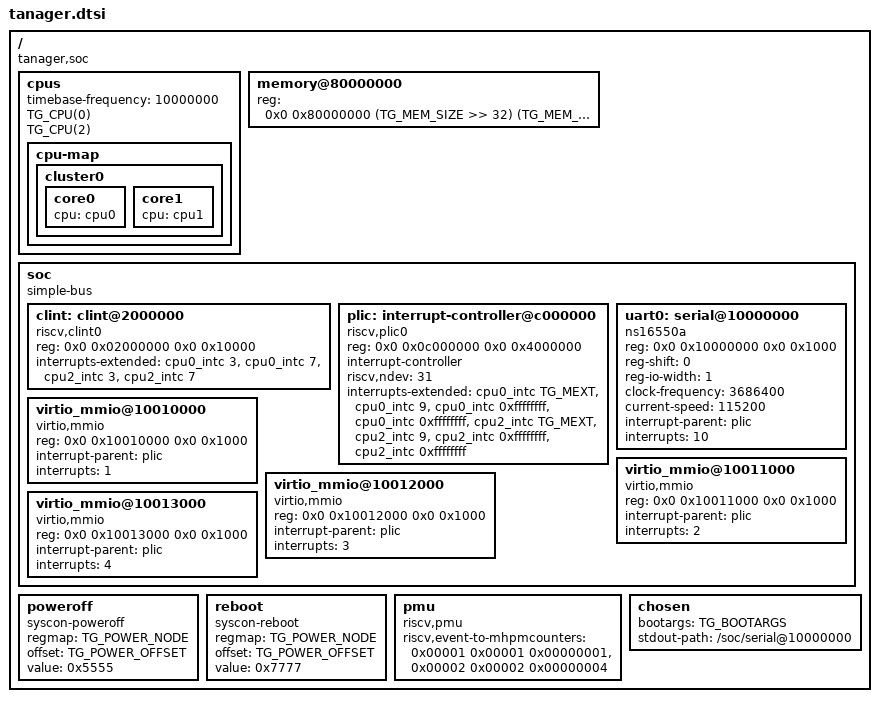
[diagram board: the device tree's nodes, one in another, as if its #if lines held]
// Tanager platform device tree: the plan §5.4 memory map (docs/spec/soc.md §4).
// Preprocessed with cpp before dtc. The including .dts defines:
// Every MMIO node's reg covers whole 4 KiB pages, base and size (soc.md §4; the build checks it, check_pages.py):
// OpenSBI makes a PMP region of each device it uses, and one smaller than a page costs every 4K page its cached PMP
// result in the core: -23.6% on a store loop and +10% on rdtime in RISC-V mode, from a 4-byte syscon (10-21).
//   TG_NUM_CORES (1|2), TG_NUM_THREADS (1|2)   harts = cores x threads, mhartid = core * threads + tid
//   TG_RUN_THREADS (default TG_NUM_THREADS)     1 with TG_NUM_THREADS 2: an SMT2 build that runs thread 0
//                                               of each core (until M7, DR-147): harts 0 and 2 only
//   TG_MEM_SIZE                                 DRAM bytes at 0x8000_0000 (64-bit expression)
//   TG_FPU (0|1)                                1 when the core implements F and D
//   TG_POWER_NODE                               label of the syscon that takes the power-off/reboot writes
//   TG_POWER_OFFSET                             byte offset of the power register in that syscon
//   TG_PMU (0|1)                                1 adds the riscv,pmu node (the bench image, DR-141)
//   TG_HPM (0|1)                                1 for a core built with TG_HPM (M9's counters, DR-190): Sscofpmf
//                                               in the ISA strings, and the riscv,pmu node maps the events to
//                                               mhpmcounter3-6; never for a core without them
//   TG_UART1 (0|1)                              1 adds the PS's UART1 through the PS window as the stdout
//                                               path (stage D's D3, DR-163; TG_PS_WINDOW=1 bitstreams)
//   TG_UART1_STDOUT (0|1)                       with TG_UART1, 0 keeps the stdout path on the PL UART (D4's
//                                               RISC-V mode: Debian's plain earlycon follows it; default 1)
//   TG_ETH (0|1)                                1 adds the PS's GEM3 and its PHY through the PS window (D5)
//   TG_ETH_MAC                                  with TG_ETH, its MAC address as bytes ("00 0a 35 ...")
//   TG_SD1 (0|1)                                1 adds the PS's SD1 through the PS window (stage D's D4)
//   TG_INITRD (0|1)                             1 names tanager-host's initrd window in /chosen (D4)
//   TG_BOARD_RESET (0|1)                        1 points reboot and poweroff at the board's reset, CRL_APB
//                                               RESET_CTRL through the PS window (D4's RISC-V mode)
//   TG_RELEASE (0|1)                            1: a release build's PLIC (DR-180), with no M-mode contexts
// Values written to the power register (same as the sifive,test0 finisher): 0x5555 off, 0x7777 reboot.

#define TG_HARTS (TG_NUM_CORES * TG_NUM_THREADS)
#ifndef TG_RUN_THREADS
#define TG_RUN_THREADS TG_NUM_THREADS
#endif
#define TG_T0ONLY (TG_NUM_THREADS == 2 && TG_RUN_THREADS == 1)
#ifndef TG_RELEASE
#define TG_RELEASE 0
#endif
// A hart's M-mode PLIC context: machine external (11), or absent (-1) in a release build, whose PLIC builds none
// (DR-180): OpenSBI and Linux skip it, and the hart's S context keeps its place, 2h+1
#if TG_RELEASE
#define TG_MEXT 0xffffffff
#else
#define TG_MEXT 11
#endif
#ifndef TG_UART1
#define TG_UART1 0
#endif
#ifndef TG_SD1
#define TG_SD1 0
#endif
#ifndef TG_INITRD
#define TG_INITRD 0
#endif
#ifndef TG_BOARD_RESET
#define TG_BOARD_RESET 0
#endif
#ifndef TG_UART1_STDOUT
#define TG_UART1_STDOUT 1
#endif
#ifndef TG_ETH
#define TG_ETH 0
#endif
#ifndef TG_HPM
#define TG_HPM 0
#endif

// The ISA strings (DR-194, M9 §10): each extension the RTL meets, checked against docs/spec/m9-isa-check.md, in the
// canonical order (Z by category, then S). zkt since core-2's timing audit (no operand-dependent early-out in tg_alu or
// tg_mul; a cycle-exact directed test); svinval stays out, as here it would only be SFENCE.VMA. Sscofpmf only with TG_HPM: OpenSBI and Linux take the counters' overflow interrupt and mode filters
// from it. TG_ISA_PRE194 (QEMU's tree) keeps the list from before DR-194
#ifndef TG_ISA_PRE194
#define TG_ISA_PRE194 0
#endif
#if TG_ISA_PRE194 && TG_FPU
#define TG_ISA_STR "rv64imafdc_zicsr_zifencei_zba_zbb_zbs_zicond_sstc"
#define TG_ISA_EXT "i", "m", "a", "f", "d", "c", "zicsr", "zifencei", "zba", "zbb", "zbs", "zicond", "sstc"
#elif TG_ISA_PRE194
#define TG_ISA_STR "rv64imac_zicsr_zifencei_zba_zbb_zbs_zicond_sstc"
#define TG_ISA_EXT "i", "m", "a", "c", "zicsr", "zifencei", "zba", "zbb", "zbs", "zicond", "sstc"
#elif TG_FPU && TG_HPM
#define TG_ISA_STR "rv64imafdc_zicntr_zicond_zicsr_zifencei_zihintpause_zihpm_za64rs_zba_zbb_zbs_zkt_sscofpmf_sstc"
#define TG_ISA_EXT "i", "m", "a", "f", "d", "c", "zicntr", "zicond", "zicsr", "zifencei", "zihintpause", "zihpm", \
                   "za64rs", "zba", "zbb", "zbs", "zkt", "sscofpmf", "sstc"
#elif TG_FPU
#define TG_ISA_STR "rv64imafdc_zicntr_zicond_zicsr_zifencei_zihintpause_zihpm_za64rs_zba_zbb_zbs_zkt_sstc"
#define TG_ISA_EXT "i", "m", "a", "f", "d", "c", "zicntr", "zicond", "zicsr", "zifencei", "zihintpause", "zihpm", \
                   "za64rs", "zba", "zbb", "zbs", "zkt", "sstc"
#elif TG_HPM
#define TG_ISA_STR "rv64imac_zicntr_zicond_zicsr_zifencei_zihintpause_zihpm_za64rs_zba_zbb_zbs_zkt_sscofpmf_sstc"
#define TG_ISA_EXT "i", "m", "a", "c", "zicntr", "zicond", "zicsr", "zifencei", "zihintpause", "zihpm", "za64rs", \
                   "zba", "zbb", "zbs", "zkt", "sscofpmf", "sstc"
#else
#define TG_ISA_STR "rv64imac_zicntr_zicond_zicsr_zifencei_zihintpause_zihpm_za64rs_zba_zbb_zbs_zkt_sstc"
#define TG_ISA_EXT "i", "m", "a", "c", "zicntr", "zicond", "zicsr", "zifencei", "zihintpause", "zihpm", "za64rs", \
                   "zba", "zbb", "zbs", "zkt", "sstc"
#endif

#define TG_CPU(n)                                                       \
	cpu##n: cpu@n {                                                 \
		device_type = "cpu";                                    \
		reg = <n>;                                              \
		compatible = "tanager,tanager", "riscv";                \
		riscv,isa = TG_ISA_STR;                                 \
		riscv,isa-base = "rv64i";                               \
		riscv,isa-extensions = TG_ISA_EXT;                      \
		mmu-type = "riscv,sv39";                                \
		status = "okay";                                        \
		cpu##n##_intc: interrupt-controller {                   \
			#interrupt-cells = <1>;                         \
			compatible = "riscv,cpu-intc";                  \
			interrupt-controller;                           \
		};                                                      \
	}

/ {
	#address-cells = <2>;
	#size-cells = <2>;
	compatible = "tanager,soc";

	cpus {
		#address-cells = <1>;
		#size-cells = <0>;
		timebase-frequency = <10000000>;	// ACLINT mtime: tg_map_pkg::TIMEBASE_HZ

		TG_CPU(0);
#if TG_T0ONLY
#if TG_NUM_CORES > 1
		TG_CPU(2);
#endif
#else
#if TG_HARTS > 1
		TG_CPU(1);
#endif
#if TG_HARTS > 2
		TG_CPU(2);
		TG_CPU(3);
#endif
#endif

		cpu-map {
			cluster0 {
#if TG_NUM_THREADS == 1
				core0 { cpu = <&cpu0>; };
#if TG_NUM_CORES > 1
				core1 { cpu = <&cpu1>; };
#endif
#elif TG_T0ONLY
				core0 { thread0 { cpu = <&cpu0>; }; };
#if TG_NUM_CORES > 1
				core1 { thread0 { cpu = <&cpu2>; }; };
#endif
#else
				core0 {
					thread0 { cpu = <&cpu0>; };
					thread1 { cpu = <&cpu1>; };
				};
#if TG_NUM_CORES > 1
				core1 {
					thread0 { cpu = <&cpu2>; };
					thread1 { cpu = <&cpu3>; };
				};
#endif
#endif
			};
		};
	};

	memory@80000000 {
		device_type = "memory";
		reg = <0x0 0x80000000 (TG_MEM_SIZE >> 32) (TG_MEM_SIZE & 0xffffffff)>;
	};

	soc {
		#address-cells = <2>;
		#size-cells = <2>;
		compatible = "simple-bus";
		ranges;

		// ACLINT MSWI + MTIMER in the CLINT layout: msip at 0x0, mtimecmp at 0x4000, mtime at 0xbff8.
		// Interrupt pairs per hart: 3 = machine software, 7 = machine timer.
		clint: clint@2000000 {
			compatible = "riscv,clint0";
			reg = <0x0 0x02000000 0x0 0x10000>;
			interrupts-extended = <&cpu0_intc 3 &cpu0_intc 7
#if TG_T0ONLY
#if TG_NUM_CORES > 1
					       &cpu2_intc 3 &cpu2_intc 7
#endif
#else
#if TG_HARTS > 1
					       &cpu1_intc 3 &cpu1_intc 7
#endif
#if TG_HARTS > 2
					       &cpu2_intc 3 &cpu2_intc 7
					       &cpu3_intc 3 &cpu3_intc 7
#endif
#endif
					      >;
		};

		// PLIC: contexts 2h (machine) and 2h+1 (supervisor) for hart h; 11 = machine external,
		// 9 = supervisor external (a release build: no machine contexts, TG_MEXT). Sources: 1-4 virtio
		// slots, 10 UART, 11 host mailbox.
		plic: interrupt-controller@c000000 {
			compatible = "riscv,plic0";
			reg = <0x0 0x0c000000 0x0 0x4000000>;
			#address-cells = <0>;
			#interrupt-cells = <1>;
			interrupt-controller;
			riscv,ndev = <31>;
			interrupts-extended = <&cpu0_intc TG_MEXT &cpu0_intc 9
#if TG_T0ONLY
					       // an idle thread's contexts stay in the list, unused (-1), so the
					       // hardware's context 2h, 2h+1 for hart h keeps its place
					       &cpu0_intc 0xffffffff &cpu0_intc 0xffffffff
#if TG_NUM_CORES > 1
					       &cpu2_intc TG_MEXT &cpu2_intc 9
					       &cpu2_intc 0xffffffff &cpu2_intc 0xffffffff
#endif
#else
#if TG_HARTS > 1
					       &cpu1_intc TG_MEXT &cpu1_intc 9
#endif
#if TG_HARTS > 2
					       &cpu2_intc TG_MEXT &cpu2_intc 9
					       &cpu3_intc TG_MEXT &cpu3_intc 9
#endif
#endif
					      >;
		};

		uart0: serial@10000000 {
			compatible = "ns16550a";
			reg = <0x0 0x10000000 0x0 0x1000>;
			reg-shift = <0>;
			reg-io-width = <1>;
			clock-frequency = <3686400>;	// the UART's baud reference, emulated from clk_core
			current-speed = <115200>;
			interrupt-parent = <&plic>;
			interrupts = <10>;
		};

#if TG_UART1
		// The PS's UART1 through the PS window (docs/spec/soc.md §8.2, stage D's D3, DR-163): the board's
		// USB serial port, once the A53 has released it; PLIC source 20. No clock-frequency, so OpenSBI
		// keeps the baud rate the A53 set; Linux's driver takes the clocks below.
		uart1: serial@ff010000 {
			compatible = "xlnx,zynqmp-uart", "cdns,uart-r1p12";
			reg = <0x0 0xff010000 0x0 0x1000>;
			interrupt-parent = <&plic>;
			interrupts = <20>;
			clocks = <&uart1_ref>, <&lpd_lsbus>;
			clock-names = "uart_clk", "pclk";
			current-speed = <115200>;
		};
#endif

#if TG_SD1 || TG_ETH
		// The PS's DMA masters through the PS window: their DMA reaches the RISC-V's RAM through HPM1 and the host
		// DMA port (D-c): bus address 0x5_0000_0000 + offset, coherent.
		ps-dma-bus {
			compatible = "simple-bus";
			#address-cells = <2>;
			#size-cells = <2>;
			ranges;
			dma-ranges = <0x5 0x0 0x0 0x80000000 (TG_MEM_SIZE >> 32) (TG_MEM_SIZE & 0xffffffff)>;

#if TG_SD1
			// SD1 (docs/spec/soc.md §8.2, stage D's D4): the board's card, in the A53's mode (SD high-speed,
			// 50 MHz, 3.3 V; D4's probe), PLIC source 21. The ZynqMP variant without #clock-cells: its quirks
			// (default speed at 19 MHz, auto-CMD12 reads), no PMU firmware calls, and the tap delays riscv.scr
			// sets.
			sd1: mmc@ff170000 {
				compatible = "xlnx,zynqmp-8.9a", "arasan,sdhci-8.9a";
				reg = <0x0 0xff170000 0x0 0x1000>;
				interrupt-parent = <&plic>;
				interrupts = <21>;
				clocks = <&sd1_ref>, <&lpd_lsbus>;
				clock-names = "clk_xin", "clk_ahb";
				bus-width = <4>;
				max-frequency = <50000000>;
				no-1-8-v;
				disable-wp;
			};
#endif
#if TG_ETH
			// GEM3 (D5, docs/spec/soc-d5-gem3.md): the board's Ethernet port, RGMII to the carrier's DP83867 at
			// MDIO address 1 with the A53's tree's properties; riscv.scr takes the PHY out of reset, since the PS
			// GPIO isn't in the PS window. Both queue interrupts on PLIC source 22. Fixed clocks, so the transmit
			// clock can't follow a slower link: 1 Gb/s only. No resets or power domains: macb then calls nothing
			// outside the GEM.
			gem3: ethernet@ff0e0000 {
				compatible = "xlnx,zynqmp-gem", "cdns,gem";
				reg = <0x0 0xff0e0000 0x0 0x1000>;
				interrupt-parent = <&plic>;
				interrupts = <22>, <22>;
				clocks = <&lpd_lsbus>, <&gem3_ref>, <&gem3_ref>, <&gem3_ref>, <&gem_tsu>;
				clock-names = "pclk", "hclk", "tx_clk", "rx_clk", "tsu_clk";
				phy-mode = "rgmii-id";
				phy-handle = <&gem3_phy>;
#ifdef TG_ETH_MAC
				local-mac-address = [TG_ETH_MAC];
#endif

				mdio {
					#address-cells = <1>;
					#size-cells = <0>;

					gem3_phy: ethernet-phy@1 {
						compatible = "ethernet-phy-id2000.a231";
						reg = <1>;
						ti,rx-internal-delay = <8>;
						ti,tx-internal-delay = <10>;
						ti,fifo-depth = <1>;
						ti,dp83867-rxctrl-strap-quirk;
					};
				};
			};
#endif
		};
#endif

#if TG_BOARD_RESET
		// The board's reset (D4's RISC-V mode, docs/spec/soc-d4-modes.md): CRL_APB RESET_CTRL through the PS
		// window, which passes that word while the host's BOARD_CTRL[1] is set (riscv.scr sets it). Its
		// SOFT_RESET bit resets the PS and the PL, and the A53's U-Boot chooses the mode again.
		// The syscon spans RESET_CTRL's whole 4 KiB page (the window still passes that word alone): OpenSBI
		// gives a reset syscon a PMP region of the syscon's size. Until DR-182 a region smaller than a page
		// cleared the core's "every 4K page is PMP-homogeneous" flag (tg_csr pmp_al), so no 4K page cached its
		// PMP result and every store and fetch redirect took the slow check: RISC-V mode's memory gap (10-21)
		crl_reset: syscon@ff5e0000 {
			compatible = "syscon";
			reg = <0x0 0xff5e0000 0x0 0x1000>;
		};
#endif

#if TG_VIRTIO
		// The forwarded virtio window (docs/spec/soc.md §8.1): four virtio-mmio slots whose registers
		// tanager-host serves, PLIC sources 1-4. Only for bitstreams built with it (TG_VIRTIO_WINDOW=1,
		// CAPS[2]): without it the slots answer denied. A slot the host doesn't serve reads 0, no device.
		virtio_mmio@10010000 {
			compatible = "virtio,mmio";
			reg = <0x0 0x10010000 0x0 0x1000>;
			interrupt-parent = <&plic>;
			interrupts = <1>;
		};
		virtio_mmio@10011000 {
			compatible = "virtio,mmio";
			reg = <0x0 0x10011000 0x0 0x1000>;
			interrupt-parent = <&plic>;
			interrupts = <2>;
		};
		virtio_mmio@10012000 {
			compatible = "virtio,mmio";
			reg = <0x0 0x10012000 0x0 0x1000>;
			interrupt-parent = <&plic>;
			interrupts = <3>;
		};
		virtio_mmio@10013000 {
			compatible = "virtio,mmio";
			reg = <0x0 0x10013000 0x0 0x1000>;
			interrupt-parent = <&plic>;
			interrupts = <4>;
		};
#endif
	};

#if TG_BOARD_RESET
	// The KV260 can't power itself off: poweroff resets the board too, and the boot mode record says what comes
	// next (Debian's clean shutdown keeps RISC-V mode; tanager-mode arm first gives Ubuntu)
	poweroff {
		compatible = "syscon-poweroff";
		regmap = <&crl_reset>;
		offset = <0x218>;              // RESET_CTRL
		value = <0x10>;
		mask = <0x10>;
	};

	reboot {
		compatible = "syscon-reboot";
		regmap = <&crl_reset>;
		offset = <0x218>;
		value = <0x10>;
		mask = <0x10>;
	};
#else
	poweroff {
		compatible = "syscon-poweroff";
		regmap = <&TG_POWER_NODE>;
		offset = <TG_POWER_OFFSET>;
		value = <0x5555>;
	};

	reboot {
		compatible = "syscon-reboot";
		regmap = <&TG_POWER_NODE>;
		offset = <TG_POWER_OFFSET>;
		value = <0x7777>;
	};
#endif

#if TG_PMU || TG_HPM
	// OpenSBI's PMU event map (its riscv,pmu binding; OpenSBI removes the property before Linux sees
	// it). Without TG_HPM the core has only mcycle and minstret (no mhpmcounters): CPU_CYCLES on counter 0 and
	// INSTRUCTIONS on counter 2. Without the map, SBI v3's event-info probe reports neither, so
	// Linux's PMU driver can never start them and a user-mode rdcycle reads a stopped counter.
	pmu {
		compatible = "riscv,pmu";
#if TG_HPM
		// With TG_HPM (M9's counters, DR-190; fpu-2's events): mhpmcounter3-6 (bitmap 0x78) count mhpmevent's
		// event: 1 cycles, 2 instructions retired, 3 branch mispredicts (at execute, wrong-path ones too),
		// 4 ordering replays, 5 L1D load misses, 6 data TLB walks, 7 fetch TLB walks, 8 I$ misses, 9 CoRR
		// replays, 10 the walker's busy cycles, 11 L1D store misses. The SBI events with a hardware one:
		// CPU_CYCLES and INSTRUCTIONS on their fixed counters (0, 2) and on 3-6 too, where an overflow interrupt
		// lets perf record sample them; BRANCH_MISSES (0x6), the L1D, L1I, DTLB and ITLB read misses (0x10001,
		// 0x10009, 0x10019, 0x10021) and the L1D write misses (0x10003); raw events 1-11
		riscv,event-to-mhpmevent = <0x00001 0x0 0x1>, <0x00002 0x0 0x2>, <0x00006 0x0 0x3>,
		                           <0x10001 0x0 0x5>, <0x10009 0x0 0x8>, <0x10019 0x0 0x6>,
		                           <0x10021 0x0 0x7>, <0x10003 0x0 0xb>;
		riscv,event-to-mhpmcounters = <0x00001 0x00001 0x00000079>, <0x00002 0x00002 0x0000007c>,
		                              <0x00006 0x00006 0x00000078>, <0x10001 0x10001 0x00000078>,
		                              <0x10009 0x10009 0x00000078>, <0x10019 0x10019 0x00000078>,
		                              <0x10021 0x10021 0x00000078>, <0x10003 0x10003 0x00000078>;
		riscv,raw-event-to-mhpmcounters = <0x0 0x1 0xffffffff 0xffffffff 0x78>, <0x0 0x2 0xffffffff 0xffffffff 0x78>,
		                                  <0x0 0x3 0xffffffff 0xffffffff 0x78>, <0x0 0x4 0xffffffff 0xffffffff 0x78>,
		                                  <0x0 0x5 0xffffffff 0xffffffff 0x78>, <0x0 0x6 0xffffffff 0xffffffff 0x78>,
		                                  <0x0 0x7 0xffffffff 0xffffffff 0x78>, <0x0 0x8 0xffffffff 0xffffffff 0x78>,
		                                  <0x0 0x9 0xffffffff 0xffffffff 0x78>, <0x0 0xa 0xffffffff 0xffffffff 0x78>,
		                                  <0x0 0xb 0xffffffff 0xffffffff 0x78>;
#else
		riscv,event-to-mhpmcounters = <0x00001 0x00001 0x00000001>, <0x00002 0x00002 0x00000004>;
#endif
	};
#endif

	// The PS clocks of UART1 and SD1, as the A53's clock tree reports them (D0): uart1_ref and lpd_lsbus at
	// 99,999,999 Hz, sdio1_ref at 166,666,665 Hz
#if TG_UART1
	uart1_ref: clock-uart1-ref {
		compatible = "fixed-clock";
		#clock-cells = <0>;
		clock-frequency = <99999999>;
	};

#endif
#if TG_SD1
	sd1_ref: clock-sdio1-ref {
		compatible = "fixed-clock";
		#clock-cells = <0>;
		clock-frequency = <166666665>;
	};

#endif
#if TG_ETH
	// GEM3's: gem3_ref (its hclk, tx_clk and rx_clk) and gem_tsu at the rates the A53's Linux reports (D5 step 0)
	gem3_ref: clock-gem3-ref {
		compatible = "fixed-clock";
		#clock-cells = <0>;
		clock-frequency = <124999999>;
	};

	gem_tsu: clock-gem-tsu {
		compatible = "fixed-clock";
		#clock-cells = <0>;
		clock-frequency = <249999998>;
	};

#endif
#if TG_UART1 || TG_SD1 || TG_ETH
	lpd_lsbus: clock-lpd-lsbus {
		compatible = "fixed-clock";
		#clock-cells = <0>;
		clock-frequency = <99999999>;
	};

#endif
	chosen {
		bootargs = TG_BOOTARGS;
#if TG_INITRD
		// tanager-host load --initrd: the file at 0x8800_0000, zero to the end (Linux's unpacker skips zeros)
		linux,initrd-start = <0x0 0x88000000>;
		linux,initrd-end = <0x0 0x8c000000>;
#endif
#if TG_UART1 && TG_UART1_STDOUT
		stdout-path = "/soc/serial@ff010000";
#else
		stdout-path = "/soc/serial@10000000";
#endif
	};
};
